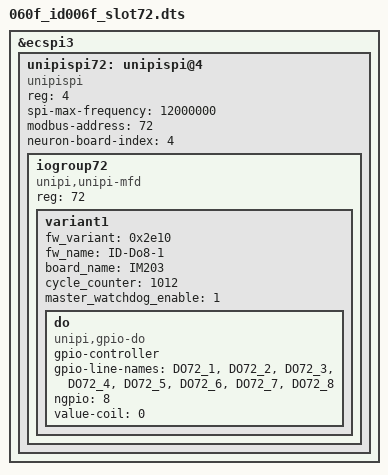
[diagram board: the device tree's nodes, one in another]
/dts-v1/;


/plugin/;

/ {
	fragment@1 {
		
		target = <&ecspi3>;
		__overlay__ {
			status = "okay";
			#address-cells = <1>;
			#size-cells = <0>;

			unipispi72: unipispi@4 {
				compatible = "unipispi";
				reg = <4>;
				status = "okay";
				spi-max-frequency = <12000000>;
				modbus-address = <72>;
				neuron-board-index = <4>;
			};
		};

	};

	fragment@2 {
		target = <&unipispi72>;
		__overlay__ {
			#address-cells = <1>;
			#size-cells = <0>;

			iogroup72 {
				reg = <72>;
				compatible = "unipi,unipi-mfd", "iogroup";
				variant1 { 
					fw_variant = <0x2e10>;
					fw_name = "ID-Do8-1";
					board_name = "IM203";
					cycle_counter = <1012>;
					master_watchdog_enable = <1>;

					do {
						compatible = "unipi,gpio-do";
						gpio-controller;
						#gpio-cells = <2>;
						gpio-line-names = "DO72_1", "DO72_2" , "DO72_3", "DO72_4", "DO72_5", "DO72_6", "DO72_7", "DO72_8";
						ngpio = <8>;
						value-coil = <0>;
					};
				};
			};
		};
	};
};
